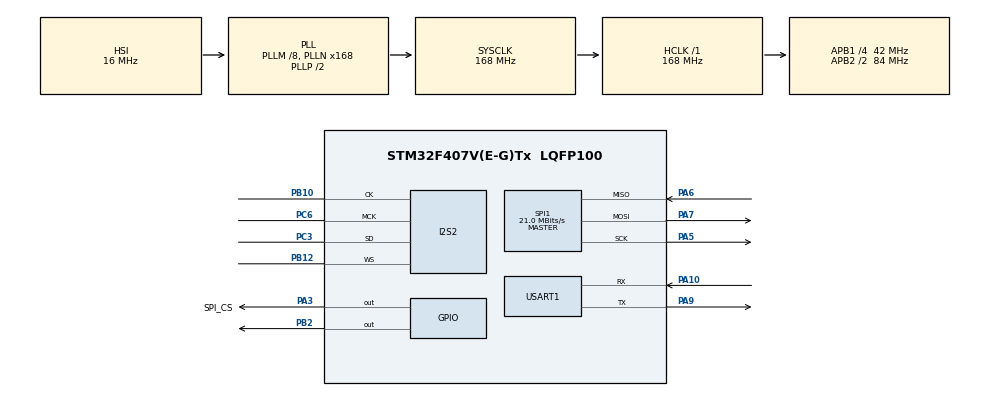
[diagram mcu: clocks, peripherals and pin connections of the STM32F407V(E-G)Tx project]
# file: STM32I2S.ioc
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Dma.Request0=SPI2_TX
Dma.Request1=SPI1_RX
Dma.SPI1_RX.1.Direction=DMA_PERIPH_TO_MEMORY
Dma.SPI1_RX.1.FIFOMode=DMA_FIFOMODE_ENABLE
Dma.SPI1_RX.1.FIFOThreshold=DMA_FIFO_THRESHOLD_FULL
Dma.SPI1_RX.1.Instance=DMA2_Stream0
Dma.SPI1_RX.1.MemBurst=DMA_MBURST_SINGLE
Dma.SPI1_RX.1.MemDataAlignment=DMA_MDATAALIGN_BYTE
Dma.SPI1_RX.1.MemInc=DMA_MINC_ENABLE
Dma.SPI1_RX.1.Mode=DMA_CIRCULAR
Dma.SPI1_RX.1.PeriphBurst=DMA_PBURST_SINGLE
Dma.SPI1_RX.1.PeriphDataAlignment=DMA_PDATAALIGN_BYTE
Dma.SPI1_RX.1.PeriphInc=DMA_PINC_DISABLE
Dma.SPI1_RX.1.Priority=DMA_PRIORITY_LOW
Dma.SPI2_TX.0.Direction=DMA_MEMORY_TO_PERIPH
Dma.SPI2_TX.0.FIFOMode=DMA_FIFOMODE_ENABLE
Dma.SPI2_TX.0.FIFOThreshold=DMA_FIFO_THRESHOLD_FULL
Dma.SPI2_TX.0.Instance=DMA1_Stream4
Dma.SPI2_TX.0.MemBurst=DMA_MBURST_SINGLE
Dma.SPI2_TX.0.MemDataAlignment=DMA_MDATAALIGN_BYTE
Dma.SPI2_TX.0.MemInc=DMA_MINC_ENABLE
Dma.SPI2_TX.0.Mode=DMA_CIRCULAR
Dma.SPI2_TX.0.PeriphBurst=DMA_PBURST_SINGLE
Dma.SPI2_TX.0.PeriphDataAlignment=DMA_PDATAALIGN_HALFWORD
Dma.SPI2_TX.0.PeriphInc=DMA_PINC_DISABLE
Dma.SPI2_TX.0.Priority=DMA_PRIORITY_LOW
FATFS._CODE_PAGE=437
FATFS._USE_FIND=1
I2S2.AudioFreq=I2S_AUDIOFREQ_44K
I2S2.ErrorAudioFreq=-0.56 %
I2S2.FullDuplexMode=I2S_FULLDUPLEXMODE_DISABLE
I2S2.Instance=SPI$Index
I2S2.RealAudioFreq=43.75 KHz
I2S2.VirtualMode=I2S_MODE_MASTER
Mcu.Family=STM32F4
Mcu.Name=STM32F407V(E-G)Tx
Mcu.Package=LQFP100
NVIC.DMA1_Stream4_IRQn=true\:0\:0\:false\:false\:true\:false\:true\:true
NVIC.DMA2_Stream0_IRQn=true\:0\:0\:false\:false\:true\:false\:true\:true
NVIC.PriorityGroup=NVIC_PRIORITYGROUP_4
PA10.Mode=Asynchronous
PA10.Signal=USART1_RX
PA13.Mode=Serial_Wire
PA13.Signal=SYS_JTMS-SWDIO
PA14.Mode=Serial_Wire
PA14.Signal=SYS_JTCK-SWCLK
PA3.GPIO_Label=SPI_CS
PA3.GPIO_ModeDefaultOutputPP=GPIO_MODE_OUTPUT_PP
PA3.GPIO_PuPd=GPIO_NOPULL
PA3.Signal=GPIO_Output
PA5.Mode=Full_Duplex_Master
PA5.Signal=SPI1_SCK
PA6.Mode=Full_Duplex_Master
PA6.Signal=SPI1_MISO
PA7.Mode=Full_Duplex_Master
PA7.Signal=SPI1_MOSI
PA9.Mode=Asynchronous
PA9.Signal=USART1_TX
PB10.Mode=Half_Duplex_Master
PB10.Signal=I2S2_CK
PB12.Mode=Half_Duplex_Master
PB12.Signal=I2S2_WS
PB2.Signal=GPIO_Output
PC14-OSC32_IN.Mode=LSE-External-Oscillator
PC14-OSC32_IN.Signal=RCC_OSC32_IN
PC15-OSC32_OUT.Mode=LSE-External-Oscillator
PC15-OSC32_OUT.Signal=RCC_OSC32_OUT
PC3.Mode=Half_Duplex_Master
PC3.Signal=I2S2_SD
PC6.Mode=Master_Clock_Activated
PC6.Signal=I2S2_MCK
PH0-OSC_IN.Mode=HSE-External-Oscillator
PH0-OSC_IN.Signal=RCC_OSC_IN
PH1-OSC_OUT.Mode=HSE-External-Oscillator
PH1-OSC_OUT.Signal=RCC_OSC_OUT
ProjectManager.HeapSize=0x200
ProjectManager.StackSize=0x2600
ProjectManager.TargetToolchain=MDK-ARM V5.32
RCC.48MHZClocksFreq_Value=84000000
RCC.AHBFreq_Value=168000000
RCC.APB1CLKDivider=RCC_HCLK_DIV4
RCC.APB1Freq_Value=42000000
RCC.APB1TimFreq_Value=84000000
RCC.APB2CLKDivider=RCC_HCLK_DIV2
RCC.APB2Freq_Value=84000000
RCC.APB2TimFreq_Value=168000000
RCC.CortexFreq_Value=168000000
RCC.HCLKFreq_Value=168000000
RCC.HSE_VALUE=25000000
RCC.HSI_VALUE=16000000
RCC.PLLI2SN=168
RCC.PLLM=8
RCC.PLLN=168
RCC.SYSCLKFreq_VALUE=168000000
RCC.SYSCLKSource=RCC_SYSCLKSOURCE_PLLCLK
RCC.VCOOutputFreq_Value=336000000
SPI1.BaudRatePrescaler=SPI_BAUDRATEPRESCALER_4
SPI1.CalculateBaudRate=21.0 MBits/s
SPI1.Direction=SPI_DIRECTION_2LINES
SPI1.Mode=SPI_MODE_MASTER
SPI1.VirtualType=VM_MASTER
USART1.VirtualMode=VM_ASYNC
VP_FATFS_VS_Generic.Mode=User_defined
board=custom

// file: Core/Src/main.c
/* USER CODE BEGIN Header */
/**
  ******************************************************************************
  * @file           : main.c
  * @brief          : Main program body
  ******************************************************************************
  * @attention
  *
  * Copyright (c) 2025 STMicroelectronics.
  * All rights reserved.
  *
  * This software is licensed under terms that can be found in the LICENSE file
  * in the root directory of this software component.
  * If no LICENSE file comes with this software, it is provided AS-IS.
  *
  ******************************************************************************
  */
/* USER CODE END Header */
#include "main.h"
#include "dma.h"
#include "fatfs.h"
#include "i2s.h"
#include "spi.h"
#include "usart.h"
#include "gpio.h"

/* USER CODE BEGIN Includes */
#include "sd.h"
/* USER CODE END Includes */

void SystemClock_Config(void);

int main(void)
{

  /* MCU Configuration--------------------------------------------------------*/

  /* Reset of all peripherals, Initializes the Flash interface and the Systick. */
  HAL_Init();

  /* Configure the system clock */
  SystemClock_Config();

  /* Initialize all configured peripherals */
  MX_GPIO_Init();
  MX_DMA_Init();
  MX_I2S2_Init();
  MX_USART1_UART_Init();
  MX_SPI1_Init();
  MX_FATFS_Init();
  /* USER CODE BEGIN 2 */
printf("Runuing...\r\n");

Get_SDCard_Capacity();
  /* USER CODE END 2 */

  /* Infinite loop */
  /* USER CODE BEGIN WHILE */
  while (1)
  {

    HAL_GPIO_TogglePin(GPIOB,GPIO_PIN_2);
		HAL_Delay(500);

    /* USER CODE END WHILE */

  }
}

void SystemClock_Config(void)
{
  RCC_OscInitTypeDef RCC_OscInitStruct = {0};
  RCC_ClkInitTypeDef RCC_ClkInitStruct = {0};

  /** Configure the main internal regulator output voltage
  */
  __HAL_RCC_PWR_CLK_ENABLE();
  __HAL_PWR_VOLTAGESCALING_CONFIG(PWR_REGULATOR_VOLTAGE_SCALE1);

  /** Initializes the RCC Oscillators according to the specified parameters
  * in the RCC_OscInitTypeDef structure.
  */
  RCC_OscInitStruct.OscillatorType = RCC_OSCILLATORTYPE_HSI;
  RCC_OscInitStruct.HSIState = RCC_HSI_ON;
  RCC_OscInitStruct.HSICalibrationValue = RCC_HSICALIBRATION_DEFAULT;
  RCC_OscInitStruct.PLL.PLLState = RCC_PLL_ON;
  RCC_OscInitStruct.PLL.PLLSource = RCC_PLLSOURCE_HSI;
  RCC_OscInitStruct.PLL.PLLM = 8;
  RCC_OscInitStruct.PLL.PLLN = 168;
  RCC_OscInitStruct.PLL.PLLP = RCC_PLLP_DIV2;
  RCC_OscInitStruct.PLL.PLLQ = 4;
  if (HAL_RCC_OscConfig(&RCC_OscInitStruct) != HAL_OK)
  {
    Error_Handler();
  }

  /** Initializes the CPU, AHB and APB buses clocks
  */
  RCC_ClkInitStruct.ClockType = RCC_CLOCKTYPE_HCLK|RCC_CLOCKTYPE_SYSCLK
                              |RCC_CLOCKTYPE_PCLK1|RCC_CLOCKTYPE_PCLK2;
  RCC_ClkInitStruct.SYSCLKSource = RCC_SYSCLKSOURCE_PLLCLK;
  RCC_ClkInitStruct.AHBCLKDivider = RCC_SYSCLK_DIV1;
  RCC_ClkInitStruct.APB1CLKDivider = RCC_HCLK_DIV4;
  RCC_ClkInitStruct.APB2CLKDivider = RCC_HCLK_DIV2;

  if (HAL_RCC_ClockConfig(&RCC_ClkInitStruct, FLASH_LATENCY_5) != HAL_OK)
  {
    Error_Handler();
  }
}

void Error_Handler(void)
{
  __disable_irq();
  while (1)
  {
  }
}
